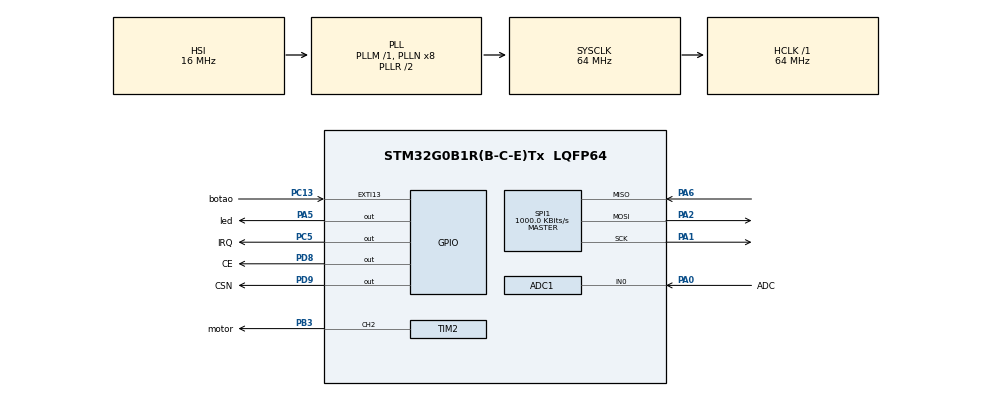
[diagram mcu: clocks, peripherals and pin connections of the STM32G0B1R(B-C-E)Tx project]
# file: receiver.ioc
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ADC1.Channel-0\#ChannelRegularConversion=ADC_CHANNEL_0
ADC1.NbrOfConversionFlag=1
ADC1.Rank-0\#ChannelRegularConversion=1
ADC1.SamplingTime-0\#ChannelRegularConversion=ADC_SAMPLINGTIME_COMMON_1
ADC1.SamplingTimeCommon1=ADC_SAMPLETIME_39CYCLES_5
ADC1.SamplingTimeCommon2=ADC_SAMPLETIME_39CYCLES_5
ADC1.SelectedChannel=ADC_CHANNEL_0
ADC1.master=1
Dma.ADC1.0.Direction=DMA_PERIPH_TO_MEMORY
Dma.ADC1.0.EventEnable=DISABLE
Dma.ADC1.0.Instance=DMA1_Channel1
Dma.ADC1.0.MemDataAlignment=DMA_MDATAALIGN_WORD
Dma.ADC1.0.MemInc=DMA_MINC_ENABLE
Dma.ADC1.0.Mode=DMA_CIRCULAR
Dma.ADC1.0.PeriphDataAlignment=DMA_PDATAALIGN_WORD
Dma.ADC1.0.PeriphInc=DMA_PINC_DISABLE
Dma.ADC1.0.Polarity=HAL_DMAMUX_REQ_GEN_RISING
Dma.ADC1.0.Priority=DMA_PRIORITY_LOW
Dma.ADC1.0.RequestNumber=1
Dma.ADC1.0.SignalID=NONE
Dma.ADC1.0.SyncEnable=DISABLE
Dma.ADC1.0.SyncPolarity=HAL_DMAMUX_SYNC_NO_EVENT
Dma.ADC1.0.SyncRequestNumber=1
Dma.ADC1.0.SyncSignalID=NONE
Dma.Request0=ADC1
Mcu.Family=STM32G0
Mcu.Name=STM32G0B1R(B-C-E)Tx
Mcu.Package=LQFP64
NVIC.DMA1_Channel1_IRQn=true\:0\:0\:false\:false\:true\:false\:true
NVIC.SPI1_IRQn=true\:0\:0\:false\:false\:true\:true\:true
NVIC.TIM16_FDCAN_IT0_IRQn=true\:0\:0\:false\:false\:true\:true\:true
NVIC.TIM2_IRQn=true\:0\:0\:false\:false\:true\:true\:true
NVIC.TIM7_LPTIM2_IRQn=true\:0\:0\:false\:false\:true\:true\:true
PA0.GPIO_Label=ADC
PA0.Mode=IN0
PA0.Signal=ADC1_IN0
PA1.Mode=Full_Duplex_Master
PA1.Signal=SPI1_SCK
PA13.Mode=Serial_Wire
PA13.Signal=SYS_SWDIO
PA14-BOOT0.Mode=Serial_Wire
PA14-BOOT0.Signal=SYS_SWCLK
PA2.Mode=Full_Duplex_Master
PA2.Signal=SPI1_MOSI
PA5.GPIO_Label=led
PA5.Signal=GPIO_Output
PA6.Mode=Full_Duplex_Master
PA6.Signal=SPI1_MISO
PB3.GPIO_Label=motor
PB3.Signal=S_TIM2_CH2
PC13.GPIO_Label=botao
PC13.Signal=GPXTI13
PC5.GPIO_Label=IRQ
PC5.Signal=GPIO_Output
PD8.GPIO_Label=CE
PD8.Signal=GPIO_Output
PD9.GPIO_Label=CSN
PD9.Signal=GPIO_Output
ProjectManager.HeapSize=0x200
ProjectManager.StackSize=0x400
ProjectManager.TargetToolchain=STM32CubeIDE
RCC.ADCFreq_Value=64000000
RCC.AHBFreq_Value=64000000
RCC.CortexFreq_Value=64000000
RCC.EXTERNAL_CLOCK_VALUE=48000
RCC.HCLKFreq_Value=64000000
RCC.HSE_VALUE=8000000
RCC.HSI48_VALUE=48000000
RCC.HSI_VALUE=16000000
RCC.LSE_VALUE=32768
RCC.SYSCLKFreq_VALUE=64000000
RCC.SYSCLKSource=RCC_SYSCLKSOURCE_PLLCLK
RCC.USBFreq_Value=48000000
RCC.VCOOutputFreq_Value=128000000
SH.S_TIM2_CH2.0=TIM2_CH2,PWM Generation2 CH2
SPI1.BaudRatePrescaler=SPI_BAUDRATEPRESCALER_64
SPI1.CalculateBaudRate=1000.0 KBits/s
SPI1.Direction=SPI_DIRECTION_2LINES
SPI1.Mode=SPI_MODE_MASTER
SPI1.VirtualType=VM_MASTER
TIM16.Period=63999
TIM16.Prescaler=199
TIM2.Channel-PWM\ Generation2\ CH2=TIM_CHANNEL_2
TIM2.Period=999
TIM2.Prescaler=63
TIM7.Period=6400
TIM7.Prescaler=9999
VP_SYS_VS_DBSignals.Mode=DisableDeadBatterySignals
VP_TIM16_VS_ClockSourceINT.Mode=Enable_Timer
VP_TIM2_VS_ClockSourceINT.Mode=Internal
VP_TIM7_VS_ClockSourceINT.Mode=Enable_Timer
board=custom

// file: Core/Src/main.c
/* USER CODE BEGIN Header */
/**
  ******************************************************************************
  * @file           : main.c
  * @brief          : Main program body
  ******************************************************************************
  * @attention
  *
  * Copyright (c) 2022 STMicroelectronics.
  * All rights reserved.
  *
  * This software is licensed under terms that can be found in the LICENSE file
  * in the root directory of this software component.
  * If no LICENSE file comes with this software, it is provided AS-IS.
  *
  ******************************************************************************
  */
/* USER CODE END Header */
#include "main.h"

/* USER CODE BEGIN Includes */
#include "app.h"
/* USER CODE END Includes */

ADC_HandleTypeDef hadc1;
DMA_HandleTypeDef hdma_adc1;

SPI_HandleTypeDef hspi1;

TIM_HandleTypeDef htim2;
TIM_HandleTypeDef htim7;
TIM_HandleTypeDef htim16;

/* USER CODE BEGIN PV */

/* NRF24L01 RECEIVER */
extern uint8_t data_array[2];
extern uint8_t data_transmit[2];

/* MOTOR */
extern uint32_t value;
extern float corrente;
extern uint16_t vel;
/* USER CODE END PV */

void SystemClock_Config(void);
static void MX_ADC1_Init(void);
static void MX_GPIO_Init(void);
static void MX_SPI1_Init(void);
static void MX_TIM2_Init(void);
static void MX_DMA_Init(void);
static void MX_TIM16_Init(void);
static void MX_TIM7_Init(void);

int main(void)
{

  /* MCU Configuration--------------------------------------------------------*/

  /* Reset of all peripherals, Initializes the Flash interface and the Systick. */
  HAL_Init();

  /* Configure the system clock */
  SystemClock_Config();

  /* Initialize all configured peripherals */
  MX_ADC1_Init();
  MX_GPIO_Init();
  MX_SPI1_Init();
  MX_TIM2_Init();
  MX_DMA_Init();
  MX_TIM16_Init();
  MX_TIM7_Init();
  /* USER CODE BEGIN 2 */
  app_init();
  app_run();
  /* USER CODE END 2 */

  /* Infinite loop */
  while (1)
  {

  }
}

void SystemClock_Config(void)
{
  RCC_OscInitTypeDef RCC_OscInitStruct = {0};
  RCC_ClkInitTypeDef RCC_ClkInitStruct = {0};

  /** Configure the main internal regulator output voltage
  */
  HAL_PWREx_ControlVoltageScaling(PWR_REGULATOR_VOLTAGE_SCALE1);
  /** Initializes the RCC Oscillators according to the specified parameters
  * in the RCC_OscInitTypeDef structure.
  */
  RCC_OscInitStruct.OscillatorType = RCC_OSCILLATORTYPE_HSI;
  RCC_OscInitStruct.HSIState = RCC_HSI_ON;
  RCC_OscInitStruct.HSIDiv = RCC_HSI_DIV1;
  RCC_OscInitStruct.HSICalibrationValue = RCC_HSICALIBRATION_DEFAULT;
  RCC_OscInitStruct.PLL.PLLState = RCC_PLL_ON;
  RCC_OscInitStruct.PLL.PLLSource = RCC_PLLSOURCE_HSI;
  RCC_OscInitStruct.PLL.PLLM = RCC_PLLM_DIV1;
  RCC_OscInitStruct.PLL.PLLN = 8;
  RCC_OscInitStruct.PLL.PLLP = RCC_PLLP_DIV2;
  RCC_OscInitStruct.PLL.PLLQ = RCC_PLLQ_DIV2;
  RCC_OscInitStruct.PLL.PLLR = RCC_PLLR_DIV2;
  if (HAL_RCC_OscConfig(&RCC_OscInitStruct) != HAL_OK)
  {
    Error_Handler();
  }
  /** Initializes the CPU, AHB and APB buses clocks
  */
  RCC_ClkInitStruct.ClockType = RCC_CLOCKTYPE_HCLK|RCC_CLOCKTYPE_SYSCLK
                              |RCC_CLOCKTYPE_PCLK1;
  RCC_ClkInitStruct.SYSCLKSource = RCC_SYSCLKSOURCE_PLLCLK;
  RCC_ClkInitStruct.AHBCLKDivider = RCC_SYSCLK_DIV1;
  RCC_ClkInitStruct.APB1CLKDivider = RCC_HCLK_DIV1;

  if (HAL_RCC_ClockConfig(&RCC_ClkInitStruct, FLASH_LATENCY_2) != HAL_OK)
  {
    Error_Handler();
  }
}

static void MX_ADC1_Init(void)
{

  ADC_ChannelConfTypeDef sConfig = {0};

  /** Configure the global features of the ADC (Clock, Resolution, Data Alignment and number of conversion)
  */
  hadc1.Instance = ADC1;
  hadc1.Init.ClockPrescaler = ADC_CLOCK_SYNC_PCLK_DIV2;
  hadc1.Init.Resolution = ADC_RESOLUTION_12B;
  hadc1.Init.DataAlign = ADC_DATAALIGN_RIGHT;
  hadc1.Init.ScanConvMode = ADC_SCAN_DISABLE;
  hadc1.Init.EOCSelection = ADC_EOC_SINGLE_CONV;
  hadc1.Init.LowPowerAutoWait = DISABLE;
  hadc1.Init.LowPowerAutoPowerOff = DISABLE;
  hadc1.Init.ContinuousConvMode = DISABLE;
  hadc1.Init.NbrOfConversion = 1;
  hadc1.Init.DiscontinuousConvMode = DISABLE;
  hadc1.Init.ExternalTrigConv = ADC_SOFTWARE_START;
  hadc1.Init.ExternalTrigConvEdge = ADC_EXTERNALTRIGCONVEDGE_NONE;
  hadc1.Init.DMAContinuousRequests = DISABLE;
  hadc1.Init.Overrun = ADC_OVR_DATA_PRESERVED;
  hadc1.Init.SamplingTimeCommon1 = ADC_SAMPLETIME_39CYCLES_5;
  hadc1.Init.SamplingTimeCommon2 = ADC_SAMPLETIME_39CYCLES_5;
  hadc1.Init.OversamplingMode = DISABLE;
  hadc1.Init.TriggerFrequencyMode = ADC_TRIGGER_FREQ_HIGH;
  if (HAL_ADC_Init(&hadc1) != HAL_OK)
  {
    Error_Handler();
  }
  /** Configure Regular Channel
  */
  sConfig.Channel = ADC_CHANNEL_0;
  sConfig.Rank = ADC_REGULAR_RANK_1;
  sConfig.SamplingTime = ADC_SAMPLINGTIME_COMMON_1;
  if (HAL_ADC_ConfigChannel(&hadc1, &sConfig) != HAL_OK)
  {
    Error_Handler();
  }

}

static void MX_SPI1_Init(void)
{

  /* SPI1 parameter configuration*/
  hspi1.Instance = SPI1;
  hspi1.Init.Mode = SPI_MODE_MASTER;
  hspi1.Init.Direction = SPI_DIRECTION_2LINES;
  hspi1.Init.DataSize = SPI_DATASIZE_8BIT;
  hspi1.Init.CLKPolarity = SPI_POLARITY_LOW;
  hspi1.Init.CLKPhase = SPI_PHASE_1EDGE;
  hspi1.Init.NSS = SPI_NSS_SOFT;
  hspi1.Init.BaudRatePrescaler = SPI_BAUDRATEPRESCALER_64;
  hspi1.Init.FirstBit = SPI_FIRSTBIT_MSB;
  hspi1.Init.TIMode = SPI_TIMODE_DISABLE;
  hspi1.Init.CRCCalculation = SPI_CRCCALCULATION_DISABLE;
  hspi1.Init.CRCPolynomial = 7;
  hspi1.Init.CRCLength = SPI_CRC_LENGTH_DATASIZE;
  hspi1.Init.NSSPMode = SPI_NSS_PULSE_ENABLE;
  if (HAL_SPI_Init(&hspi1) != HAL_OK)
  {
    Error_Handler();
  }

}

static void MX_TIM2_Init(void)
{

  TIM_ClockConfigTypeDef sClockSourceConfig = {0};
  TIM_MasterConfigTypeDef sMasterConfig = {0};
  TIM_OC_InitTypeDef sConfigOC = {0};

  htim2.Instance = TIM2;
  htim2.Init.Prescaler = 63;
  htim2.Init.CounterMode = TIM_COUNTERMODE_UP;
  htim2.Init.Period = 999;
  htim2.Init.ClockDivision = TIM_CLOCKDIVISION_DIV1;
  htim2.Init.AutoReloadPreload = TIM_AUTORELOAD_PRELOAD_DISABLE;
  if (HAL_TIM_Base_Init(&htim2) != HAL_OK)
  {
    Error_Handler();
  }
  sClockSourceConfig.ClockSource = TIM_CLOCKSOURCE_INTERNAL;
  if (HAL_TIM_ConfigClockSource(&htim2, &sClockSourceConfig) != HAL_OK)
  {
    Error_Handler();
  }
  if (HAL_TIM_PWM_Init(&htim2) != HAL_OK)
  {
    Error_Handler();
  }
  sMasterConfig.MasterOutputTrigger = TIM_TRGO_RESET;
  sMasterConfig.MasterSlaveMode = TIM_MASTERSLAVEMODE_DISABLE;
  if (HAL_TIMEx_MasterConfigSynchronization(&htim2, &sMasterConfig) != HAL_OK)
  {
    Error_Handler();
  }
  sConfigOC.OCMode = TIM_OCMODE_PWM1;
  sConfigOC.Pulse = 0;
  sConfigOC.OCPolarity = TIM_OCPOLARITY_HIGH;
  sConfigOC.OCFastMode = TIM_OCFAST_DISABLE;
  if (HAL_TIM_PWM_ConfigChannel(&htim2, &sConfigOC, TIM_CHANNEL_2) != HAL_OK)
  {
    Error_Handler();
  }
  HAL_TIM_MspPostInit(&htim2);

}

static void MX_TIM7_Init(void)
{

  TIM_MasterConfigTypeDef sMasterConfig = {0};

  htim7.Instance = TIM7;
  htim7.Init.Prescaler = 9999;
  htim7.Init.CounterMode = TIM_COUNTERMODE_UP;
  htim7.Init.Period = 6400;
  htim7.Init.AutoReloadPreload = TIM_AUTORELOAD_PRELOAD_DISABLE;
  if (HAL_TIM_Base_Init(&htim7) != HAL_OK)
  {
    Error_Handler();
  }
  sMasterConfig.MasterOutputTrigger = TIM_TRGO_RESET;
  sMasterConfig.MasterSlaveMode = TIM_MASTERSLAVEMODE_DISABLE;
  if (HAL_TIMEx_MasterConfigSynchronization(&htim7, &sMasterConfig) != HAL_OK)
  {
    Error_Handler();
  }

}

static void MX_TIM16_Init(void)
{

  htim16.Instance = TIM16;
  htim16.Init.Prescaler = 199;
  htim16.Init.CounterMode = TIM_COUNTERMODE_UP;
  htim16.Init.Period = 63999;
  htim16.Init.ClockDivision = TIM_CLOCKDIVISION_DIV1;
  htim16.Init.RepetitionCounter = 0;
  htim16.Init.AutoReloadPreload = TIM_AUTORELOAD_PRELOAD_DISABLE;
  if (HAL_TIM_Base_Init(&htim16) != HAL_OK)
  {
    Error_Handler();
  }

}

static void MX_DMA_Init(void)
{

  /* DMA controller clock enable */
  __HAL_RCC_DMA1_CLK_ENABLE();

  /* DMA interrupt init */
  /* DMA1_Channel1_IRQn interrupt configuration */
  HAL_NVIC_SetPriority(DMA1_Channel1_IRQn, 0, 0);
  HAL_NVIC_EnableIRQ(DMA1_Channel1_IRQn);

}

static void MX_GPIO_Init(void)
{
  GPIO_InitTypeDef GPIO_InitStruct = {0};

  /* GPIO Ports Clock Enable */
  __HAL_RCC_GPIOC_CLK_ENABLE();
  __HAL_RCC_GPIOA_CLK_ENABLE();
  __HAL_RCC_GPIOD_CLK_ENABLE();
  __HAL_RCC_GPIOB_CLK_ENABLE();

  /*Configure GPIO pin Output Level */
  HAL_GPIO_WritePin(led_GPIO_Port, led_Pin, GPIO_PIN_RESET);

  /*Configure GPIO pin Output Level */
  HAL_GPIO_WritePin(IRQ_GPIO_Port, IRQ_Pin, GPIO_PIN_RESET);

  /*Configure GPIO pin Output Level */
  HAL_GPIO_WritePin(GPIOD, CE_Pin|CSN_Pin, GPIO_PIN_RESET);

  /*Configure GPIO pin : botao_Pin */
  GPIO_InitStruct.Pin = botao_Pin;
  GPIO_InitStruct.Mode = GPIO_MODE_IT_RISING;
  GPIO_InitStruct.Pull = GPIO_NOPULL;
  HAL_GPIO_Init(botao_GPIO_Port, &GPIO_InitStruct);

  /*Configure GPIO pin : led_Pin */
  GPIO_InitStruct.Pin = led_Pin;
  GPIO_InitStruct.Mode = GPIO_MODE_OUTPUT_PP;
  GPIO_InitStruct.Pull = GPIO_NOPULL;
  GPIO_InitStruct.Speed = GPIO_SPEED_FREQ_LOW;
  HAL_GPIO_Init(led_GPIO_Port, &GPIO_InitStruct);

  /*Configure GPIO pin : IRQ_Pin */
  GPIO_InitStruct.Pin = IRQ_Pin;
  GPIO_InitStruct.Mode = GPIO_MODE_OUTPUT_PP;
  GPIO_InitStruct.Pull = GPIO_NOPULL;
  GPIO_InitStruct.Speed = GPIO_SPEED_FREQ_LOW;
  HAL_GPIO_Init(IRQ_GPIO_Port, &GPIO_InitStruct);

  /*Configure GPIO pins : CE_Pin CSN_Pin */
  GPIO_InitStruct.Pin = CE_Pin|CSN_Pin;
  GPIO_InitStruct.Mode = GPIO_MODE_OUTPUT_PP;
  GPIO_InitStruct.Pull = GPIO_NOPULL;
  GPIO_InitStruct.Speed = GPIO_SPEED_FREQ_LOW;
  HAL_GPIO_Init(GPIOD, &GPIO_InitStruct);

}

void Error_Handler(void)
{
  __disable_irq();
  while (1)
  {
  }
}
